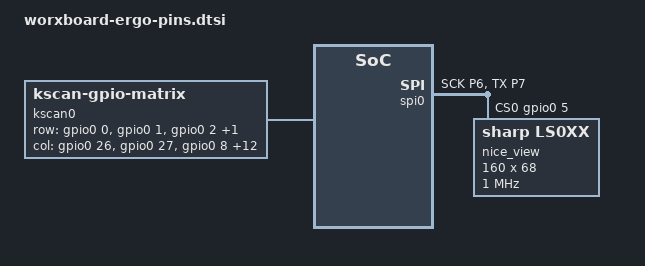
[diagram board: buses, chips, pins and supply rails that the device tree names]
/* Generated by tools/firmware_layout.py from pcb/scripts/design.py GPIO_NETS. */
/ {
 kscan0: kscan {
  compatible = "zmk,kscan-gpio-matrix";
  diode-direction = "col2row";
  row-gpios = <&gpio0 0 (GPIO_ACTIVE_HIGH | GPIO_PULL_DOWN)>,
   <&gpio0 1 (GPIO_ACTIVE_HIGH | GPIO_PULL_DOWN)>,
   <&gpio0 2 (GPIO_ACTIVE_HIGH | GPIO_PULL_DOWN)>,
   <&gpio0 3 (GPIO_ACTIVE_HIGH | GPIO_PULL_DOWN)>;
  col-gpios = <&gpio0 26 GPIO_ACTIVE_HIGH>,
   <&gpio0 27 GPIO_ACTIVE_HIGH>,
   <&gpio0 8 GPIO_ACTIVE_HIGH>,
   <&gpio0 9 GPIO_ACTIVE_HIGH>,
   <&gpio0 10 GPIO_ACTIVE_HIGH>,
   <&gpio0 11 GPIO_ACTIVE_HIGH>,
   <&gpio0 12 GPIO_ACTIVE_HIGH>,
   <&gpio0 13 GPIO_ACTIVE_HIGH>,
   <&gpio0 14 GPIO_ACTIVE_HIGH>,
   <&gpio0 15 GPIO_ACTIVE_HIGH>,
   <&gpio0 16 GPIO_ACTIVE_HIGH>,
   <&gpio0 17 GPIO_ACTIVE_HIGH>,
   <&gpio0 18 GPIO_ACTIVE_HIGH>,
   <&gpio0 19 GPIO_ACTIVE_HIGH>,
   <&gpio0 20 GPIO_ACTIVE_HIGH>;
 };
};
&pinctrl {
 spi0_default: spi0_default {
  group1 { pinmux = <SPI0_SCK_P6>, <SPI0_TX_P7>; };
 };
};
&spi0 {
 status = "okay";
 pinctrl-0 = <&spi0_default>;
 pinctrl-names = "default";
 cs-gpios = <&gpio0 5 GPIO_ACTIVE_HIGH>;
 nice_view: ls0xx@0 {
  compatible = "sharp,ls0xx";
  reg = <0>;
  spi-max-frequency = <1000000>;
  width = <160>;
  height = <68>;
  serial-vcom-inversion;
  serial-vcom-interval = <33>;
 };
};
